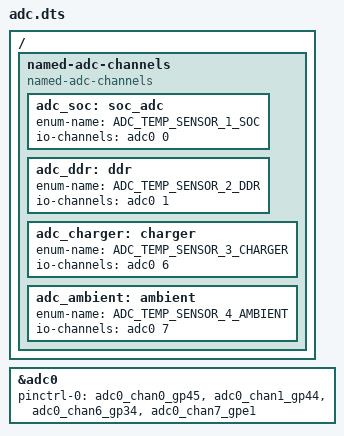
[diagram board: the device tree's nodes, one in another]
/* Copyright 2022 The ChromiumOS Authors
 * Use of this source code is governed by a BSD-style license that can be
 * found in the LICENSE file.
 */

/ {
	named-adc-channels {
		compatible = "named-adc-channels";

		adc_soc: soc_adc {
			enum-name = "ADC_TEMP_SENSOR_1_SOC";
			io-channels = <&adc0 0>;
		};
		adc_ddr: ddr {
			enum-name = "ADC_TEMP_SENSOR_2_DDR";
			io-channels = <&adc0 1>;
		};
		adc_charger: charger {
			enum-name = "ADC_TEMP_SENSOR_3_CHARGER";
			io-channels = <&adc0 6>;
		};
		adc_ambient: ambient {
			enum-name = "ADC_TEMP_SENSOR_4_AMBIENT";
			io-channels = <&adc0 7>;
		};
	};
};

&adc0 {
	status = "okay";
	pinctrl-0 = <&adc0_chan0_gp45
		     &adc0_chan1_gp44
		     &adc0_chan6_gp34
		     &adc0_chan7_gpe1>;
	pinctrl-names = "default";
};
